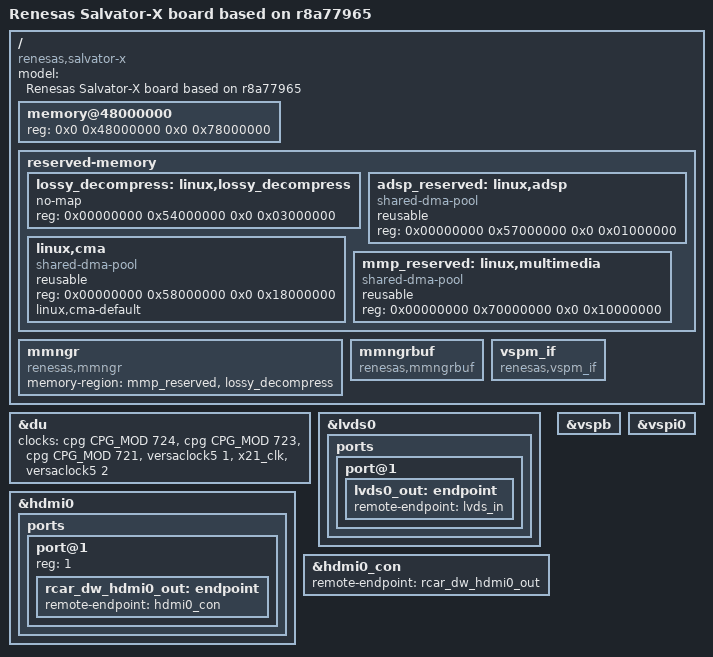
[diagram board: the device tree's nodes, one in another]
// SPDX-License-Identifier: GPL-2.0
/*
 * Device Tree Source for the Salvator-X board with R-Car M3-N
 *
 * Copyright (C) 2018 Jacopo Mondi <jacopo+renesas@jmondi.org>
 */

/dts-v1/;
#include "r8a77965.dtsi"
#include "salvator-x.dtsi"

/ {
	model = "Renesas Salvator-X board based on r8a77965";
	compatible = "renesas,salvator-x", "renesas,r8a77965";

	memory@48000000 {
		device_type = "memory";
		/* first 128MB is reserved for secure area. */
		reg = <0x0 0x48000000 0x0 0x78000000>;
	};

	reserved-memory {
		#address-cells = <2>;
		#size-cells = <2>;
		ranges;

		/* device specific region for Lossy Decompression */
		lossy_decompress: linux,lossy_decompress {
			no-map;
			reg = <0x00000000 0x54000000 0x0 0x03000000>;
		};

		/* For Audio DSP */
		adsp_reserved: linux,adsp {
			compatible = "shared-dma-pool";
			reusable;
			reg = <0x00000000 0x57000000 0x0 0x01000000>;
		};

		/* global autoconfigured region for contiguous allocations */
		linux,cma {
			compatible = "shared-dma-pool";
			reusable;
			reg = <0x00000000 0x58000000 0x0 0x18000000>;
			linux,cma-default;
		};

		/* device specific region for contiguous allocations */
		mmp_reserved: linux,multimedia {
			compatible = "shared-dma-pool";
			reusable;
			reg = <0x00000000 0x70000000 0x0 0x10000000>;
		};
	};

	mmngr {
		compatible = "renesas,mmngr";
		memory-region = <&mmp_reserved>, <&lossy_decompress>;
	};

	mmngrbuf {
		compatible = "renesas,mmngrbuf";
	};

	vspm_if {
		compatible = "renesas,vspm_if";
	};
};

&du {
	clocks = <&cpg CPG_MOD 724>,
		 <&cpg CPG_MOD 723>,
		 <&cpg CPG_MOD 721>,
		 <&versaclock5 1>,
		 <&x21_clk>,
		 <&versaclock5 2>;
	clock-names = "du.0", "du.1", "du.3",
		      "dclkin.0", "dclkin.1", "dclkin.3";
};

&lvds0 {
	ports {
		port@1 {
			lvds0_out: endpoint {
				remote-endpoint = <&lvds_in>;
			};
		};
	};
};

&hdmi0 {
	status = "okay";

	ports {
		port@1 {
			reg = <1>;
			rcar_dw_hdmi0_out: endpoint {
				remote-endpoint = <&hdmi0_con>;
			};
		};
	};
};

&hdmi0_con {
	remote-endpoint = <&rcar_dw_hdmi0_out>;
};

&vspb {
	status = "okay";
};

&vspi0 {
	status = "okay";
};
